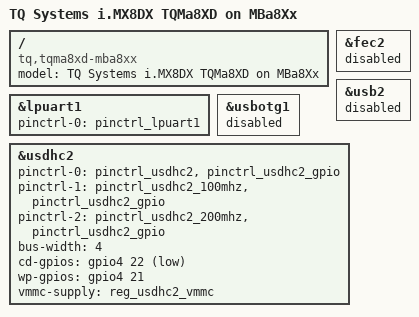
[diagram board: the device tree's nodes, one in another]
/*
 * Copyright 2019 TQ Systems GmbH
 *
 * This program is free software; you can redistribute it and/or
 * modify it under the terms of the GNU General Public License
 * as published by the Free Software Foundation; either version 2
 * of the License, or (at your option) any later version.
 *
 * This program is distributed in the hope that it will be useful,
 * but WITHOUT ANY WARRANTY; without even the implied warranty of
 * MERCHANTABILITY or FITNESS FOR A PARTICULAR PURPOSE.  See the
 * GNU General Public License for more details.
 */

#include "fsl-imx8qxp-tqma8xqp-mba8xx.dts"

/ {
	model = "TQ Systems i.MX8DX TQMa8XD on MBa8Xx";
	compatible = "tq,tqma8xd-mba8xx", "tq,tqma8xd", "fsl,imx8dx";
};

&fec2 {
	status = "disabled";
};

&lpuart1 {
	pinctrl-names = "default";
	pinctrl-0 = <&pinctrl_lpuart1>;
	status = "okay";
};

&usbotg1 {
	status = "disabled";
};

&usb2 {
	status = "disabled";
};

&usdhc2 {
	pinctrl-names = "default", "state_100mhz", "state_200mhz";
	pinctrl-0 = <&pinctrl_usdhc2>, <&pinctrl_usdhc2_gpio>;
	pinctrl-1 = <&pinctrl_usdhc2_100mhz>, <&pinctrl_usdhc2_gpio>;
	pinctrl-2 = <&pinctrl_usdhc2_200mhz>, <&pinctrl_usdhc2_gpio>;
	bus-width = <4>;
	cd-gpios = <&gpio4 22 GPIO_ACTIVE_LOW>;
	wp-gpios = <&gpio4 21 GPIO_ACTIVE_HIGH>;
	vmmc-supply = <&reg_usdhc2_vmmc>;
	status = "okay";
};
